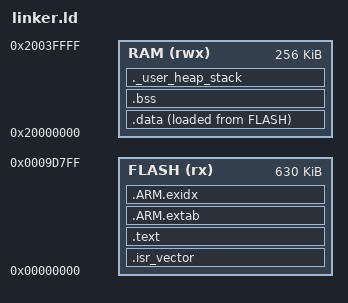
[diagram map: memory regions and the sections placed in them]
/* Linker script for LPC55S69JBD100
 * Flash: 630KB at 0x00000000 (last 10KB reserved for CMPA/CFPA)
 * SRAM:  256KB at 0x20000000 (SRAM0-3 only; SRAM4 needs separate clock)
 */

MEMORY
{
    FLASH (rx)  : ORIGIN = 0x00000000, LENGTH = 630K
    RAM   (rwx) : ORIGIN = 0x20000000, LENGTH = 256K
}

_estack = ORIGIN(RAM) + LENGTH(RAM);

ENTRY(Reset_Handler)

SECTIONS
{
    /* Vector table must be at the very start of flash */
    .isr_vector :
    {
        . = ALIGN(4);
        KEEP(*(.isr_vector))
        . = ALIGN(4);
    } > FLASH

    /* Code and read-only data */
    .text :
    {
        . = ALIGN(4);
        *(.text)
        *(.text*)
        *(.rodata)
        *(.rodata*)
        *(.glue_7)
        *(.glue_7t)
        KEEP(*(.init))
        KEEP(*(.fini))
        . = ALIGN(4);
        _etext = .;
    } > FLASH

    /* ARM exception handling - needed by some toolchains */
    .ARM.extab :
    {
        *(.ARM.extab* .gnu.linkonce.armextab.*)
    } > FLASH

    .ARM.exidx :
    {
        __exidx_start = .;
        *(.ARM.exidx* .gnu.linkonce.armexidx.*)
        __exidx_end = .;
    } > FLASH

    /* Load address of .data in flash */
    _sidata = LOADADDR(.data);

    /* Initialized data - stored in flash, copied to RAM at startup */
    .data :
    {
        . = ALIGN(4);
        _sdata = .;
        *(.data)
        *(.data*)
        . = ALIGN(4);
        _edata = .;
    } > RAM AT> FLASH

    /* Uninitialized data - zeroed at startup */
    .bss :
    {
        . = ALIGN(4);
        _sbss = .;
        __bss_start__ = _sbss;
        *(.bss)
        *(.bss*)
        *(COMMON)
        . = ALIGN(4);
        _ebss = .;
        __bss_end__ = _ebss;
    } > RAM

    /* Heap and stack check */
    ._user_heap_stack :
    {
        . = ALIGN(8);
        PROVIDE(end = .);
        PROVIDE(_end = .);
        . = . + 0x400;  /* Min 1KB heap */
        . = . + 0x800;  /* Min 2KB stack */
        . = ALIGN(8);
    } > RAM

    /* Discard debug-related stuff from standard libs */
    /DISCARD/ :
    {
        *(.comment)
        *(.note*)
    }
}
